# D1H register map
Vendor: Allwinner; File version: 1.0
Registers are 32-bit, read-write, reset 0x0 unless marked. A register's access mark holds for its fields unless they carry their own. Offsets are from the block's base; [hi:lo] are bit positions; {n}, {i} and the like mark numbered series.

## TCON_LCD0 — Timing COntroller LCD
Base 0x05461000
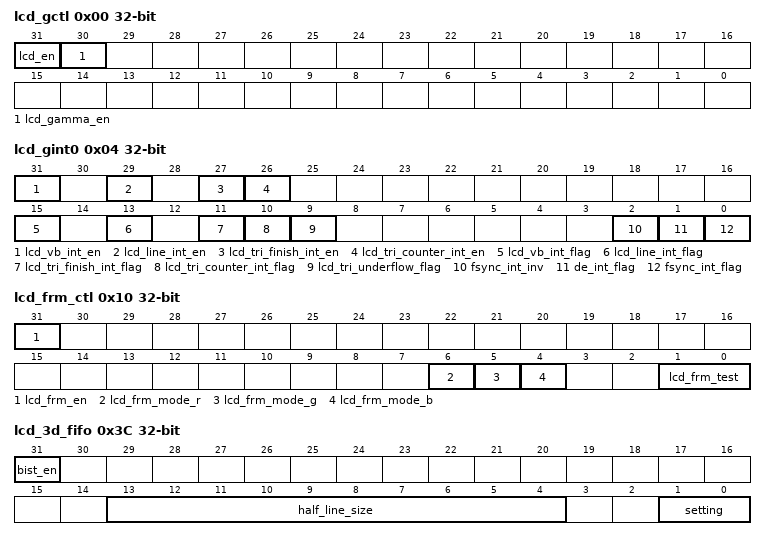
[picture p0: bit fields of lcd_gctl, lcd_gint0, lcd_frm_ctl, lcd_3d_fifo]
0x00 lcd_gctl — LCD Global Control Register
  [31] lcd_en — When it is disabled, the module will be reset to idle state.
    0=DISABLE; 1=ENABLE
  [30] lcd_gamma_en — Enable the Gamma correction function.
    0=DISABLE; 1=ENABLE
0x04 lcd_gint0 — LCD Global Interrupt Register0
  [31] lcd_vb_int_en — Enable the Vb interrupt
    0=DISABLE; 1=ENABLE
  [29] lcd_line_int_en — Enable the line interrupt
    0=DISABLE; 1=ENABLE
  [27] lcd_tri_finish_int_en — Enable the trigger finish interrupt
    0=DISABLE; 1=ENABLE
  [26] lcd_tri_counter_int_en — Enable the trigger counter interrupt
    0=DISABLE; 1=ENABLE
  [15] lcd_vb_int_flag write-0-clears — Asserted during vertical no-display period every frame . Write 0 to clear it.
  [13] lcd_line_int_flag write-0-clears — Trigger when SY0 match the current LCD scan line . Write 0 to clear it.
  [11] lcd_tri_finish_int_flag write-0-clears — Trigger when cpu trigger mode finished . Write 0 to clear it.
  [10] lcd_tri_counter_int_flag write-0-clears — Trigger when tri counter reaches this value . Write 0 to clear it.
  [9] lcd_tri_underflow_flag write-0-clears — Only used in dsi video mode, tri when sync by dsi but not finish . Write 0 to clear it.
  [2] fsync_int_inv write-0-clears — Enable the fsync interrupt to set signal inverse polarity. . When FSYNC is positive, this bit must be 1. . And vice versa.
  [1] de_int_flag write-0-clears — Asserted at the first valid line in every frame . Write 0 to clear it.
  [0] fsync_int_flag write-0-clears — Asserted at the fsync signal in every frame . Write 0 to clear it.
0x08 lcd_gint1 — LCD Global Interrupt Register1
  [27:16] lcd_line_int_num — Scan line for LCD line trigger (including inactive lines). . Setting it for the specified line for trigger0. . Note: SY0 is writable only when LINE_TRG0 is disabled.
0x10 lcd_frm_ctl — LCD FRM Control Register
  [31] lcd_frm_en — Enable the dither function
    0=DISABLE; 1=ENABLE
  [6] lcd_frm_mode_r — The R component output bits in dither function
    0=B_IT6 (6-bit frm output); 1=B_IT5 (5-bit frm output)
  [5] lcd_frm_mode_g — The G component output bits in dither function
    0=B_IT6 (6-bit frm output); 1=B_IT5 (5-bit frm output)
  [4] lcd_frm_mode_b — The B component output bits in dither function
    0=B_IT6 (6-bit frm output); 1=B_IT5 (5-bit frm output)
  [1:0] lcd_frm_test — Set the test mode of dither function
    0=FRM; 1=HALF_BIT_56_FRM (Half 5/6-bit, half FRM); 2=HALF_BIT_8_FRM (Half 8-bit, half FRM); 3=HALF_BIT_8_56 (Half 8-bit, half 5/6-bit)
{0x14+4i} lcd_frm_seed{i} (i=0..5)
  [24:0] seed_value — Set the seed used in dither function . Note: Avoid setting it to 0.
{0x2C+4i} lcd_frm_tab{i} (i=0..3) — LCD FRM Table Register
  [31:0] frm_table_value — Set the data used in dither function
0x3C lcd_3d_fifo
  [31] bist_en — Enable the 3D fifo bist test function
    0=DISABLE; 1=ENABLE
  [13:4] half_line_size — The number of data in half line=3D_FIFO_HALF_LINE_SIZE+1, only valid when 3D_FIFO_SETTING is set as 2.
  [1:0] setting — Set the work mode of 3D FIFO
    0=BYPASS; 1=NORMAL (Used as normal FIFO); 2=INTERLACE_3D (Used as 3D interlace FIFO)
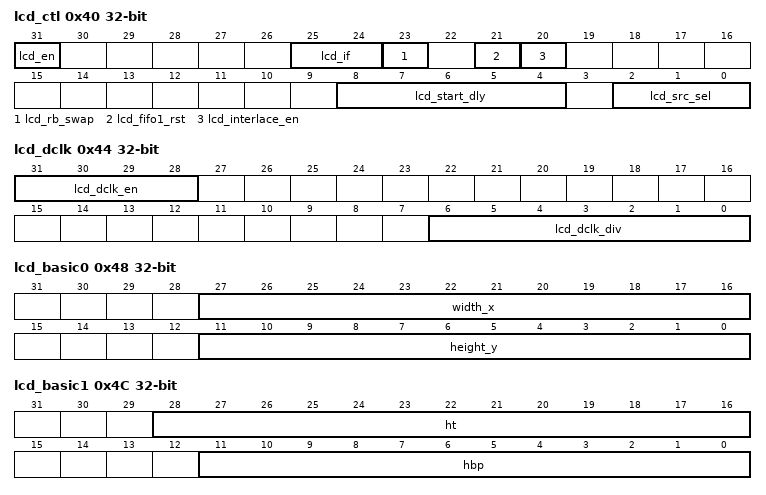
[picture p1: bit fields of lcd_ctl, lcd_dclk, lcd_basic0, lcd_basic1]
0x40 lcd_ctl — LCD Control Register
  [31] lcd_en — It executes at the beginning of the first blank line of LCD timing.
    0=DISABLE; 1=ENABLE
  [25:24] lcd_if — Set the interface type of LCD controller
    0=HV (HV (Sync + DE)); 1=IF_8080 (8080 I/F)
  [23] lcd_rb_swap — Enable the function to swap red data and blue data in fifo1.
    0=D_EFAULT; 1=S_WAP (Swap RED and BLUE data at FIFO1)
  [21] lcd_fifo1_rst — Writing 1 and then 0 to this bit will reset FIFO 1 . Note: 1 holding time must more than 1 DCLK
  [20] lcd_interlace_en — This flag is valid only when LCD_EN == 1
    0=DISABLE; 1=ENABLE
  [8:4] lcd_start_dly — The unit of delay is T_line. . Note: Valid only when LCD_EN == 1
  [2:0] lcd_src_sel — LCD Source Select
    0=DE; 1=COLOR_CHECK; 2=GRAYSCALE_CHECK; 3=BLACK_BY_WHITE_CHECK; 4=TEST_DATA_ALL_0; 5=TEST_DATA_ALL_1; 6=REVERSED; 7=GRIDDING_CHECK
0x44 lcd_dclk — LCD Data Clock Register
  [31:28] lcd_dclk_en — LCD clock enable
  [6:0] lcd_dclk_div — Tdclk = Tsclk/DCLKDIV . Note: . 1.If dclk1 and dclk2 are used, DCLKDIV >=6 . 2.If only dclk is used, DCLKDIV >=1
0x48 lcd_basic0 — LCD Basic Timing Register0
  [27:16] width_x — Panel width is X+1
  [11:0] height_y — Panel height is Y+1
0x4C lcd_basic1 — LCD Basic Timing Register1
  [28:16] ht — Thcycle = (HT+1) * Tdclk . Computation: . 1) parallel: HT = X + BLANK . Limitation: . 1) parallel: HT >= (HBP +1) + (X+1) +2 . 2) serial 1: HT >= (HBP +1) + (X+1) *3+2 . 3) serial 2: HT >= (HBP +1) + (X+1) *3/2+2
  [11:0] hbp — Horizontal back porch (in dclk) . Thbp = (HBP +1) * Tdclk
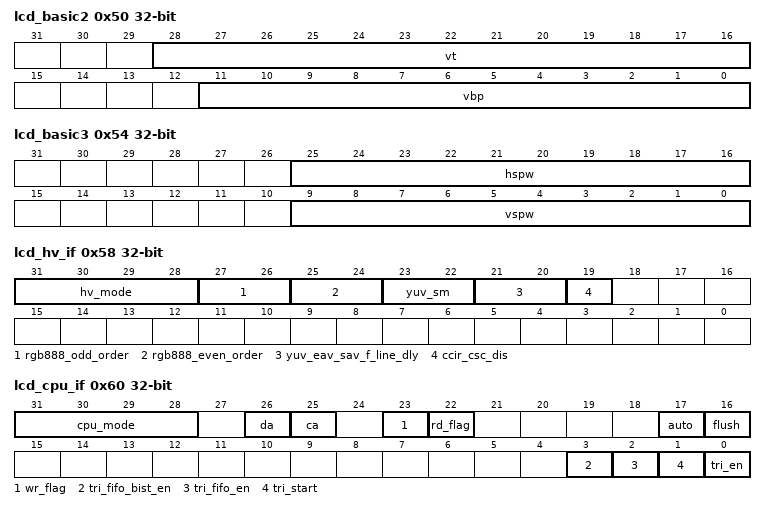
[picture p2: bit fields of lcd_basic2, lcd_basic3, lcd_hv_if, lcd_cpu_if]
0x50 lcd_basic2 — LCD Basic Timing Register2
  [28:16] vt — TVT = (VT)/2 * Thsync . VT/2 >= (VBP+1 ) + (Y+1) +2
  [11:0] vbp — Tvbp = (VBP +1) * Thsync
0x54 lcd_basic3 — LCD Basic Timing Register3
  [25:16] hspw — Thspw = (HSPW+1) * Tdclk . HT > (HSPW+1)
  [9:0] vspw — Tvspw = (VSPW+1) * Thsync . VT/2 > (VSPW+1)
0x58 lcd_hv_if — LCD HV Panel Interface Register
  [31:28] hv_mode — Set the HV mode of LCD controller
    0=PARALLEL (24-bit/1-cycle parallel mode); 8=RGB888 (8-bit/3-cycle RGB serial mode (RGB888)); 10=DRGB (8-bit/4-cycle Dummy RGB (DRGB)); 11=RGBD (8-bit/4-cycle RGB Dummy (RGBD)); 12=CCIR656 (8-bit/2-cycle YUV serial mode (CCIR656))
  [27:26] rgb888_odd_order — Serial RGB888 mode Output sequence at odd lines of the panel (line 1, 3, 5, 7...).
    0=RGB; 1=BRG; 2=GBR
  [25:24] rgb888_even_order — Serial RGB888 mode Output sequence at even lines of the panel (line 2, 4, 6, 8...).
    0=RGB; 1=BRG; 2=GBR
  [23:22] yuv_sm — Serial YUV mode Output sequence 2-pixel-pair of every scan line.
    0=YUYV; 1=YVYU; 2=UYVY; 3=VYUY
  [21:20] yuv_eav_sav_f_line_dly — Set the delay line mode.
    0=F_TOGGLE (F toggle right after active video line); 1=CCIR_PAL (delay 2 line (CCIR PAL)); 2=CCIR_NTSC (delay 3 line (CCIR NTSC))
  [19] ccir_csc_dis — LCD convert source from RGB to YUV. . Only valid when HV mode is “1100”.
    0=ENABLE; 1=DISABLE
0x60 lcd_cpu_if — LCD CPU Panel Interface Register
  [31:28] cpu_mode — Set the cpu interface work mode
    0=B_IT18_256K_MODE (18-bit/256K mode); 2=B_IT16_MODE0 (16-bit mode0); 4=B_IT16_MODE1 (16-bit mode1); 6=B_IT16_MODE2 (16-bit mode2); 8=B_IT16_MODE3 (16-bit mode3); 10=B_IT9_MODE (9-bit mode); 12=B_IT8_256K_MODE (8-bit 256K mode); 14=B_IT8_65K_MODE (8-bit 65K mode); 1=B_IT24_FOR_DSI (24-bit for DSI)
  [26] da — Pin A1 value in 8080 mode auto/flash states
  [25] ca — Pin A1 value in 8080 mode WR/RD execute
  [23] wr_flag ro — The status of write operation.
    0=FINISHING (Write operation is finishing); 1=PENDING (Write operation is pending)
  [22] rd_flag ro — The status of read operation.
    0=FINISHING (Read operation is finishing); 1=PENDING (Read operation is pending)
  [17] auto — Auto transfer mode . If it is 1, all the valid data during this frame are written to panel. . Note: This bit is sampled by Vsync.
  [16] flush — Direct transfer mode . If it is enabled, FIFO1 is regardless of the HV timing, the pixels data keep being transferred unless the input FIFO was empty. . Data output rate is controlled by DCLK.
  [3] tri_fifo_bist_en — Entry address is 0xFF8
    0=DISABLE; 1=ENABLE
  [2] tri_fifo_en — Enable the trigger FIFO
    0=DISABLE; 1=ENABLE
  [1] tri_start write-1-sets — Software must make sure that write '1' only when this flag is '0'. . Writing '1' starts a frame flush and writing '0' has no effect. . This flag indicates the frame flush is running.
  [0] tri_en — Enable trigger mode
    0=DISABLE (Trigger mode disable); 1=ENABLE (Trigger mode enable)
0x64 lcd_cpu_wr — LCD CPU Panel Write Data Register
  [23:0] data_wr wo — Data write on 8080 bus, launch a write operation on 8080 bus.
{0x68+4i} lcd_cpu_rd{i} (i=0..1) — LCD CPU Panel Read Data Register[i]
  [23:0] data_rd0 ro — Data read on 8080 bus, launch a new read operation on 8080 bus.
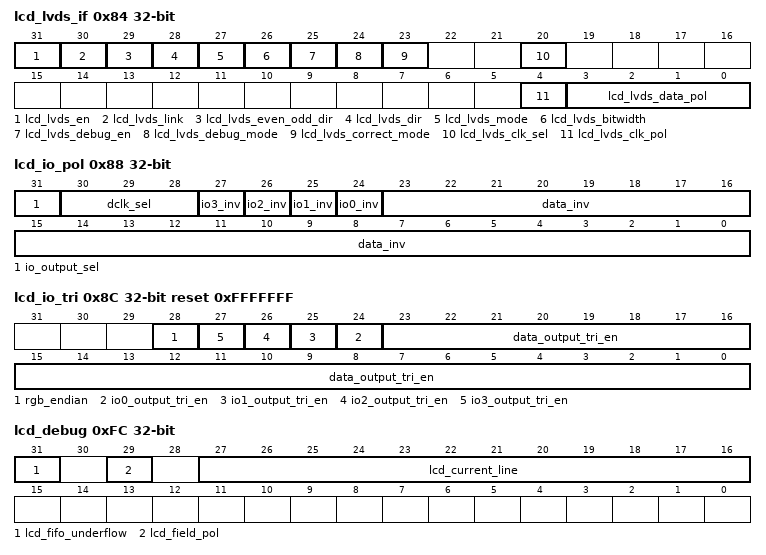
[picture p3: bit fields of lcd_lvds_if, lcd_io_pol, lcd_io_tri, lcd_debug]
0x84 lcd_lvds_if — LCD LVDS Configure Register
  [31] lcd_lvds_en — Enable LVDS interface
    0=DISABLE; 1=ENABLE
  [30] lcd_lvds_link — Select work in single link mode or dual link mode
    0=S_INGLE (Single link); 1=D_UAL (Dual link)
  [29] lcd_lvds_even_odd_dir — Set the order of even field and odd field
    0=NORMAL; 1=REVERSE
  [28] lcd_lvds_dir — Set the LVDS direction
    0=NORMAL; 1=REVERSE
  [27] lcd_lvds_mode — Set the LVDS data mode
    0=NS_MODE; 1=JEIDA_MODE
  [26] lcd_lvds_bitwidth — Set the bit width of data
    0=24_BIT; 1=18_BIT
  [25] lcd_lvds_debug_en — Enable LVDS debug function
    0=DISABLE; 1=ENABLE
  [24] lcd_lvds_debug_mode — Set the output signal in debug mode
    0=M_ODE0 (Mode0--Random data); 1=M_ODE1_O_UTPUT (Mode1--Output CLK period=7/2 LVDS CLK period)
  [23] lcd_lvds_correct_mode — Set the LVDS correct mode
    0=M_ODE0; 1=M_ODE1
  [20] lcd_lvds_clk_sel — Select the clock source of LVDS
    1=LCD (LCD CLK)
  [4] lcd_lvds_clk_pol — Set the clock polarity of LVDS
    0=REVERSE; 1=NORMAL
  [3:0] lcd_lvds_data_pol — Set the data polarity of LVDS
    0=REVERSE; 1=NORMAL
0x88 lcd_io_pol — LCD IO Polarity Register
  [31] io_output_sel — When it is set as '1', the d[23:0], io0, io1, io3 are sync to dclk.
    0=NORMAL (Normal output); 1=R_EGISTER (Register output)
  [30:28] dclk_sel — Set the phase offset of clock and data in hv mode.
    0=DCLK0 (Used DCLK0 (normal phase offset)); 1=DCLK1 (Used DCLK1 (1/3 phase offset)); 2=DCLK2 (Used DCLK2 (2/3 phase offset)); 4=DCLK02_0 (DCLK0/2 phase 0); 5=DCLK02_90 (DCLK0/2 phase 90)
  [n+24] io{n}_inv (n=0..3) — Enable invert function of IO[i]
    0=NOT_INVERT; 1=INVERT
  [23:0] data_inv — LCD output port D[23:0] polarity control, with independent bit control.
0x8C lcd_io_tri reset 0xFFFFFFF (reset mask 0x1FFFFFFF) — LCD IO Control Register
  [28] rgb_endian — Set the endian of data bits
    0=NORMAL; 1=B_ITS_INVERT
  [n+24] io{n}_output_tri_en (n=0..3) — Enable the output of IO[i]
    1=DISABLE; 0=ENABLE
  [23:0] data_output_tri_en — LCD output port D[23:0] output enable, with independent bit control.
0xFC lcd_debug
  [31] lcd_fifo_underflow ro — The flag shows whether the fifos in underflow status
    0=NOT_UNDERFLOW; 1=U_NDERFLOW
  [29] lcd_field_pol ro — The flag indicates the current field polarity
    0=SECOND; 1=FIRST
  [27:16] lcd_current_line ro — The current scan line
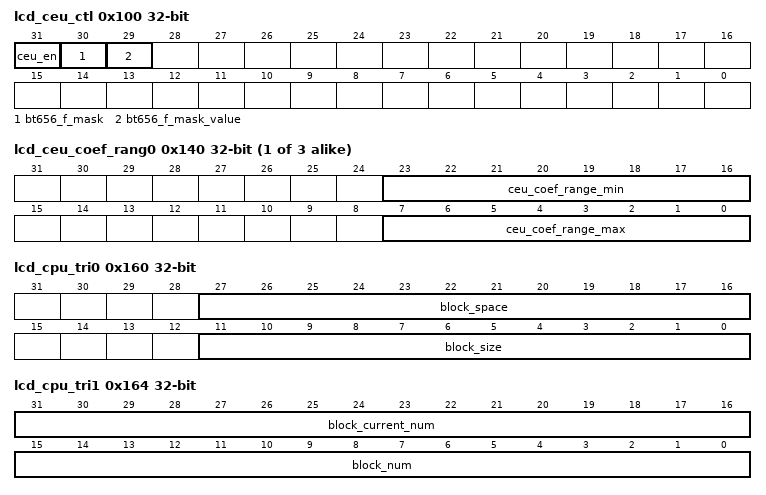
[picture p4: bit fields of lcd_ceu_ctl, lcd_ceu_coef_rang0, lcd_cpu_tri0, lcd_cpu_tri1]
0x100 lcd_ceu_ctl — LCD CEU Control Register
  [31] ceu_en — Enable CEU function
    0=BYPASS; 1=ENABLE
  [30] bt656_f_mask
    0=DISABLE; 1=ENABLE
  [29] bt656_f_mask_value
{0x110+4i} lcd_ceu_coef_mul{i} (i=0..2) — LCD CEU Coefficient Register0
  [12:0] ceu_coef_mul_value — Signed 13-bit value, range of (-16,16).
{0x11C+0x10*i} lcd_ceu_coef_add{i} (i=0..2) — LCD CEU Coefficient Register1
  [18:0] ceu_coef_add_value — Signed 19-bit value, range of (-16384, 16384).
{0x140+4i} lcd_ceu_coef_rang{i} (i=0..2) — LCD CEU Coefficient Register2
  [23:16] ceu_coef_range_min — Unsigned 8-bit value, range of [0, 255].
  [7:0] ceu_coef_range_max — Unsigned 8-bit value, range of [0, 255].
0x160 lcd_cpu_tri0 — LCD CPU Panel Trigger Register0
  [27:16] block_space — The spaces between data blocks. It should be set >20*pixel.
  [11:0] block_size — The size of data block. It is usually set as X.
0x164 lcd_cpu_tri1 — LCD CPU Panel Trigger Register1
  [31:16] block_current_num ro — Shows the current data block transmitting to panel.
  [15:0] block_num — The number of data blocks. It is usually set as Y.
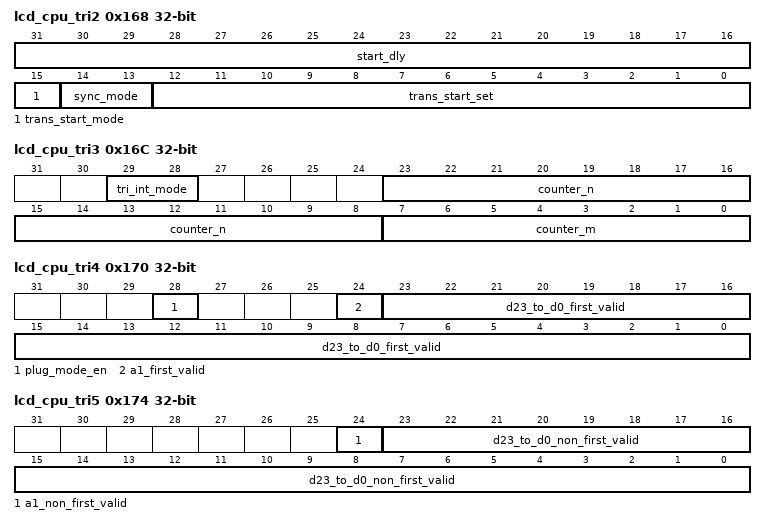
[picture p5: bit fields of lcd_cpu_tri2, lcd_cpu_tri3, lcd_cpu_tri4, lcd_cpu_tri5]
0x168 lcd_cpu_tri2 — LCD CPU Panel Trigger Register2
  [31:16] start_dly — T_dly = (Start_Delay +1) * be_clk*8.
  [15] trans_start_mode — Select the FIFOs used in CPU mode.
    0=ECC_FIFO_TRI_FIFO; 1=TRI_FIFO
  [14:13] sync_mode — Set the sync mode in CPU interface.
  [12:0] trans_start_set — Usual set as the length of a line.
0x16C lcd_cpu_tri3 — LCD CPU Panel Trigger Register3
  [29:28] tri_int_mode — When set as 01, the Tri_Counter_Int occurs in cycle of (Count_N+1) * (Count_M+1) * 4 dclk. . When set as 10 or 11, the io0 is map as TE input.
    0=DISABLE; 1=C_OUNTER (Counter mode); 2=TE_RISING (TE rising mode); 3=TE_FALLING (TE falling mode)
  [23:8] counter_n — The value of counter factor
  [7:0] counter_m — The value of counter factor
0x170 lcd_cpu_tri4 — LCD CPU Panel Trigger Register4
  [28] plug_mode_en — Enable the plug mode used in dsi command mode.
    0=DISABLE; 1=ENABLE
  [24] a1_first_valid — Valid in first Block.
  [23:0] d23_to_d0_first_valid — Valid in first Block.
0x174 lcd_cpu_tri5 — LCD CPU Panel Trigger Register5
  [24] a1_non_first_valid — Valid in Block except first.
  [23:0] d23_to_d0_non_first_valid — Valid in Block except first.
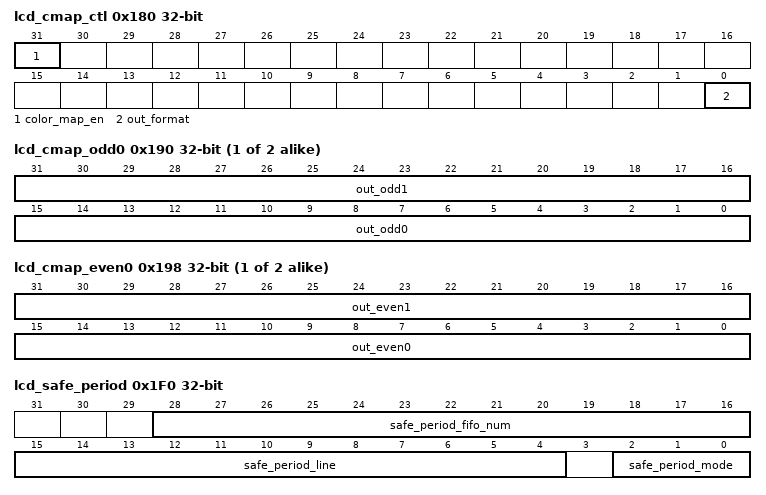
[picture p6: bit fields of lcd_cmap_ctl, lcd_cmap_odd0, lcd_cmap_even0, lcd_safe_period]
0x180 lcd_cmap_ctl — LCD Color Map Control Register
  [31] color_map_en — Enable the color map function. This module only works when X is divided by 4.
    0=BYPASS; 1=ENABLE
  [0] out_format — Set the pixel output format in color map function.
    0=P4 (4 pixel output mode: Out0 -> Out1 -> Out2 -> Out3); 1=P2 (2 pixel output mode: Out0 -> Out1)
{0x190+4i} lcd_cmap_odd{i} (i=0..1) — LCD Color Map Odd Line Register[i]
  [16n+15:16n] out_odd{n} (n=0..1) — OUT_ODD[2i + j] . Indicates the output order of components. bit15-12: Reserved bit11-08: Out_Odd[23:16] bit07-04: Out_Odd0[15:8] bit03-00: Out_Odd0[7:0]
{0x198+4i} lcd_cmap_even{i} (i=0..1) — LCD Color Map Even Line Register[i]
  [16n+15:16n] out_even{n} (n=0..1) — OUT_EVEN[2i + j] . Indicates the output order of components. bit15-12: Reserved bit11-08: Out_Even[23:16] bit07-04: Out_Even0[15:8] bit03-00: Out_Even0[7:0]
0x1F0 lcd_safe_period
  [28:16] safe_period_fifo_num — When the data length in line buffer is more than SAFE_PERIOD_FIFO_NUM, the LCD controller will allow dram controller to stop working to change frequency.
  [15:4] safe_period_line — Set a fixed line and during the line time, the LCD controller allow dram controller to change frequency. The fixed line should be set in the blanking area.
  [2:0] safe_period_mode — Select the save mode
    0=UNSAFE; 1=SAFE; 2=SAFE_FIFO_CURR_NUM_GT_SAFE_PERIOD_FIFO_NUM (safe at FIFO_CURR_NUM > SAFE_PERIOD_FIFO_NUM); 3=SAFE_2_SYNC_ACTIVE (safe at 2 and safe at sync active); 4=SAFE_LINE (safe at line)
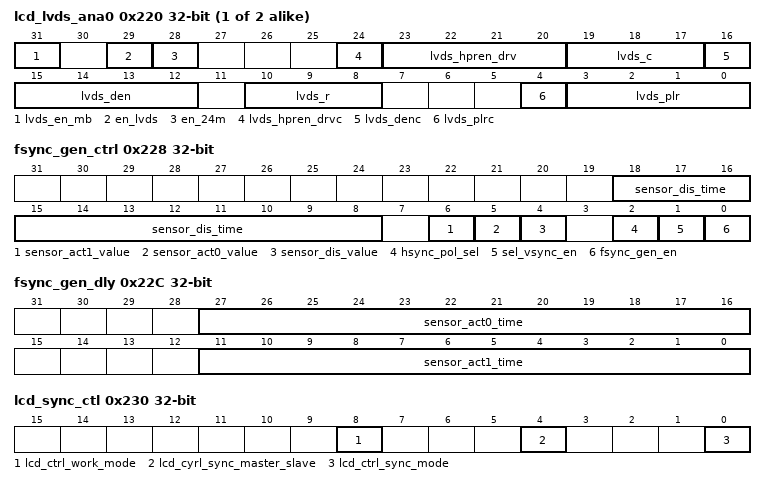
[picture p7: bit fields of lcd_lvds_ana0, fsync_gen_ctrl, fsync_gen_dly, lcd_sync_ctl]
{0x220+4i} lcd_lvds_ana{i} (i=0..1) — LCD LVDS Analog Register [i]
  [31] lvds_en_mb — Enable the bias circuit of the LVDS_Ana module.
    0=DISABLE; 1=ENABLE
  [29] en_lvds — Enable LVDS
  [28] en_24m — Enable the 24M clock
  [24] lvds_hpren_drvc — Enable clock channel drive
    0=DISABLE; 1=ENABLE
  [23:20] lvds_hpren_drv — Enable data channel[3:0] drive
  [19:17] lvds_c — Adjust current flowing through Rload of Rx to change the differential signals amplitude.
    0=216MV; 1=252MV; 2=276MV; 3=312MV; 4=336MV; 5=372MV; 6=395MV; 7=432MV
  [16] lvds_denc — Choose data output or PLL test clock output in LVDS_tx.
  [15:12] lvds_den — Choose data output or PLL test clock output in LVDS_tx.
  [10:8] lvds_r — Adjust current flowing through R of R to change the common signals amplitude.
    0=0_925_V; 1=0_950_V; 2=0_975_V; 3=1_000_V; 4=1_025_V; 5=1_050_V; 6=1_075_V; 7=1_100_V
  [4] lvds_plrc — LVDS clock channel direction.
    0=NORMAL; 1=REVERSE
  [3:0] lvds_plr — LVDS data channel [3:0] direction.
0x228 fsync_gen_ctrl
  [18:8] sensor_dis_time — Delay 0-2047 Hsync Period . When hsync_pol_sel is 0, the actual delay is sensor_dis_time-1. . When hsync_pol_sel is 1, the actual delay is sensor_dis_time.
  [6] sensor_act1_value — Sensor Active1 Value
    0=OUTPUT_0 (Fsync active_1 period output 0); 1=OUTPUT_1 (Fsync active_1 period output 1)
  [5] sensor_act0_value — Sensor Active0 Value
    0=OUTPUT_0 (Fsync active_0 period output 0); 1=OUTPUT_1 (Fsync active_0 period output 1)
  [4] sensor_dis_value — Sensor Disable Value
    0=OUTPUT_0 (Fsync disable period output 0); 1=OUTPUT_1 (Fsync disable period output 1)
  [2] hsync_pol_sel — Hsync Polarity Select
    0=NORMAL; 1=O_PPOSITE (Opposite hsync to hysnc counter)
  [1] sel_vsync_en — Select Vsync Enable
    0=FALLING (Select vsync falling edge to start state machine); 1=RISING (Select vsync rising edge to start state machine)
  [0] fsync_gen_en — Fsync Generate Enable
    0=DISABLE; 1=ENABLE
0x22C fsync_gen_dly
  [27:16] sensor_act0_time — Delay 0-4095 Pixel clk Period . The actual delay is sensor_act0_time+1.
  [11:0] sensor_act1_time — Delay 0-4095 Pixel clk Period . The actual delay is sensor_act1_time+1.
0x230 lcd_sync_ctl — LCD Sync Control Register
  [8] lcd_ctrl_work_mode — LCD Controller Work mode
    0=S_INGLE (Single DSI mode); 1=D_UAL (Dual DSI mode)
  [4] lcd_cyrl_sync_master_slave — LCD Controller Sync Master Slave . Note: Only use in Single DSI mode.
    0=M_ASTER; 1=S_LAVE
  [0] lcd_ctrl_sync_mode — LCD Controller Sync Mode . Note: Only use in Single DSI mode.
    0=S_YNC_FIRST (Sync in the first time); 1=S_YNC_EVERY (Sync every frame)
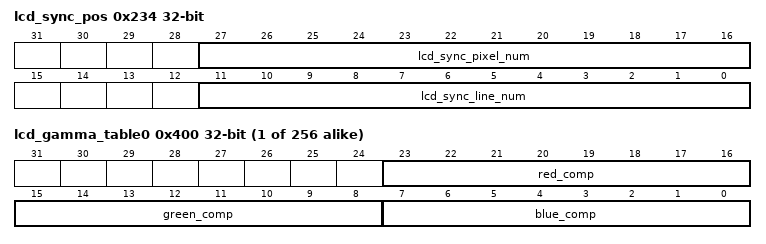
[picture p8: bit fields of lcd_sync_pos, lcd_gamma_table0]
0x234 lcd_sync_pos — LCD Sync Position Register
  [27:16] lcd_sync_pixel_num — Set the pixel number of master LCD controller which is used to trigger the slave LCD controller to start working.This value is the number of pixels between the trigger point and the end of the line. . Tri pos = Tline*LCD_Sync_Line_Num+Tpixel*(HT-LCD_Sync_Pixel_Num) . Note: Only use in Single DSI mode.
  [11:0] lcd_sync_line_num — Set the line number of master LCD controller which is used to trigger the slave LCD controller to start working. . Note:It is only set in master LCD controller.It is not necessarily to set in slave LCD controller. . Tri pos = Tline*LCD_Sync_Line_Num+Tpixel*(HT-LCD_Sync_Pixel_Num) . Note: Only use in Single DSI mode.
0x238 lcd_slave_stop_pos — LCD Slave Stop Position Register
  [7:0] stop_val — Set the stop position of the slave LCD. This value is the number of pixels between the stop position and the end of the HFP. Stop_pos = HFP - Stop_val. 0<Stop_pos<HFP-2 . Note: Only use in Single DSI mode.
{0x400+4i} lcd_gamma_table{i} (i=0..255)
  [23:16] red_comp — Red Component
  [15:8] green_comp — Green Component
  [7:0] blue_comp — Blue Component
